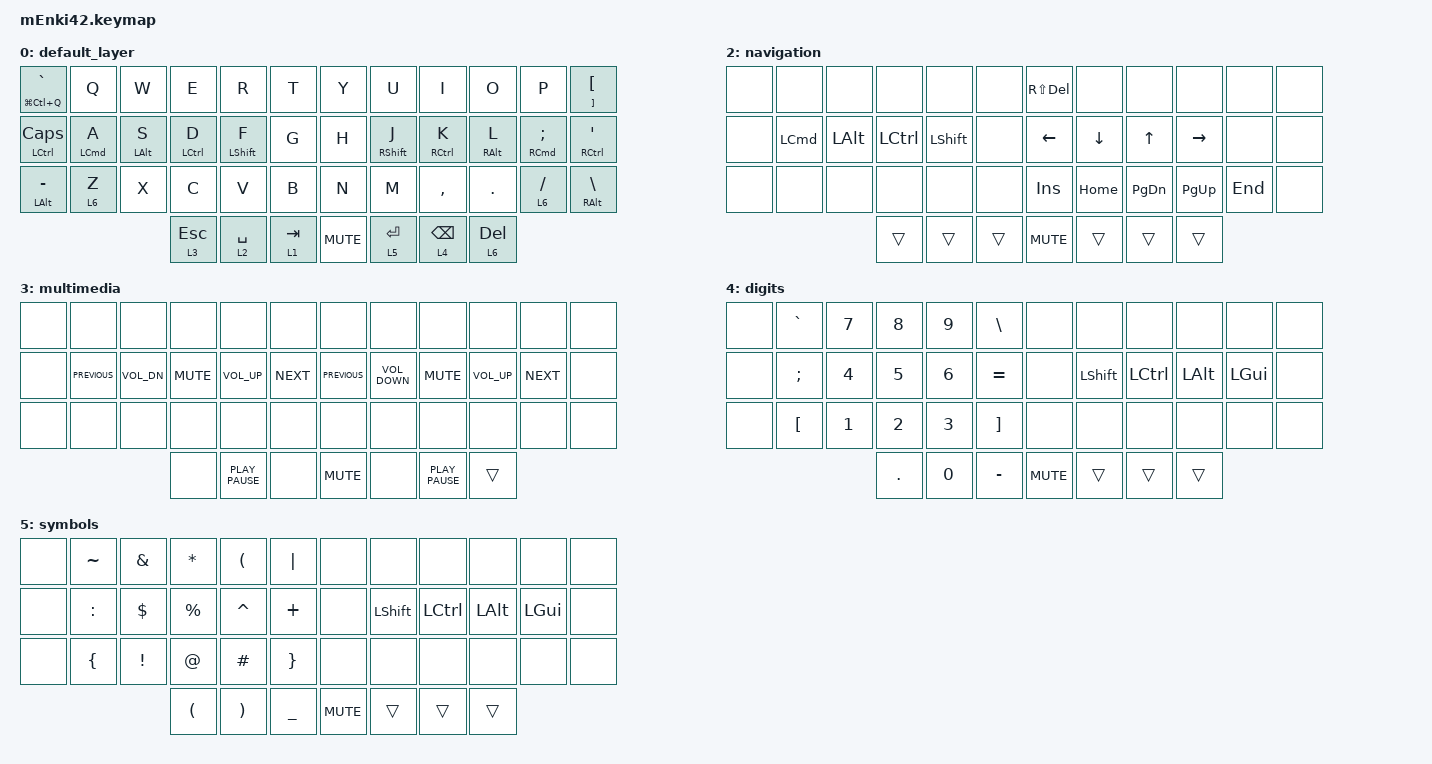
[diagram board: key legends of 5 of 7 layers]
/*
 * Copyright (c) 2020 The ZMK Contributors
 *
 * SPDX-License-Identifier: MIT
 */

#include <dt-bindings/zmk/mouse.h>
#include <behaviors.dtsi>
#include <dt-bindings/zmk/bt.h>
#include <dt-bindings/zmk/ext_power.h>
#include <dt-bindings/zmk/keys.h>

#define DEF 0
#define LWR 1
#define RSE 2
#define ADJ 3

&lt { quick_tap_ms = <220>; };

&mt {
    quick_tap_ms = <200>;
    tapping-term-ms = <250>;
    flavor = "tap-preferred";
};

/ {
    macros {
        numdot: numdot {
            label = "ZM_numdot";
            compatible = "zmk,behavior-macro";
            #binding-cells = <0>;
            wait-ms = <40>;
            tap-ms = <40>;
            bindings =
                <&macro_press>,
                <&kp LALT>,
                <&macro_tap>,
                <&kp KP_N4 &kp KP_N6>,
                <&macro_release>,
                <&kp LALT>;
        };

        grtsgn: grtsgn {
            label = "ZM_grtsgn";
            compatible = "zmk,behavior-macro";
            #binding-cells = <0>;
            wait-ms = <40>;
            tap-ms = <40>;
            bindings =
                <&macro_press>,
                <&kp LALT>,
                <&macro_tap>,
                <&kp KP_N6 &kp KP_N2>,
                <&macro_release>,
                <&kp LALT>;
        };
    };
};

/ {
    keymap {
        compatible = "zmk,keymap";

        default_layer {
            // ------------------------------------------------------------------------------------------------
            //| LGUI/] |  Q  |  W  |  E  |  R  |  T  |   |  Y  |  U   |  I  |  O  |  P  | RGUI/[ | 
            //| CTRL/` |  A  |  S  |  D  |  F  |  G  |   |  H  |  J   |  K  |  L  |  ;  | CTRL/' |
            //| LALT/\ |  Z  |  X  |  C  |  V  |  B  |   |  N  |  M   |  ,  |  .  |  /  | RALT/- |
            //                             | RSE | SPC | LWR |   | LWR | BKSP | RSE |

            bindings = <
&mt LG(LC(Q)) GRAVE  &kp Q       &kp W           &kp E        &kp R             &kp T                  &kp Y        &kp U              &kp I                &kp O            &kp P               &mt RIGHT_BRACKET LBKT
&mt LCTRL CAPSLOCK   &mt LCMD A  &mt LEFT_ALT S  &mt LCTRL D  &mt LEFT_SHIFT F  &kp G                  &kp H        &mt RIGHT_SHIFT J  &mt RIGHT_CONTROL K  &mt RIGHT_ALT L  &mt RCMD SEMICOLON  &mt RCTRL SQT
&mt LALT MINUS       &lt 6 Z     &kp X           &kp C        &kp V             &kp B                  &kp N        &kp M              &kp COMMA            &kp DOT          &lt 6 SLASH         &mt RALT BACKSLASH
                                                 &lt 3 ESC    &lt 2 SPACE       &lt 1 TAB  &kp C_MUTE  &lt 5 ENTER  &lt 4 BACKSPACE    &lt 6 DELETE
            >;

            sensor-bindings = <&inc_dec_kp C_VOL_UP C_VOL_DN>;
        };

        f {
            // -----------------------------------------------------------------------------------------
            //|LGUI/CAPS |  *  |  7 |  8  |  9  |  +  |    |  !  |  @  |  #  |  $  |  %  | RGUI/F1 |
            //|CTRL/MENU |  /  |  4 |  5  |  6  |  -  |    |  ^  |  &  |  *  |  (  |  )  | CTRL/F2 |
            //|  LALT/=  |  0  |  1 |  4  |  3  |  .  |    |  ls |  F4 |  F5 |  F6 |  F7 | RALT/F3 |
            //                      | ADJ | ___ | ___ |    | ___ | ___ | ADJ |

            bindings = <
&none  &none     &none         &none      &none           &none               &kp PRINTSCREEN  &kp F7  &kp F8  &kp F9  &kp F12  &mt RWIN F1
&none  &kp LCMD  &kp LEFT_ALT  &kp LCTRL  &kp LEFT_SHIFT  &none               &kp SCROLLLOCK   &kp F4  &kp F5  &kp F6  &kp F11  &mt RALT F2
&none  &none     &none         &none      &none           &none               &kp PAUSE_BREAK  &kp F1  &kp F2  &kp F3  &kp F10  &mt RALT F3
                               &trans     &trans          &trans  &kp C_MUTE  &trans           &trans
            >;

            sensor-bindings = <&inc_dec_kp UP_ARROW DOWN_ARROW>;
        };

        navigation {
            bindings = <
&none  &none     &none         &none      &none           &none               &kp RS(DEL)  &none     &none          &none        &none    &none
&none  &kp LCMD  &kp LEFT_ALT  &kp LCTRL  &kp LEFT_SHIFT  &none               &kp LEFT     &kp DOWN  &kp UP_ARROW   &kp RIGHT    &none    &none
&none  &none     &none         &none      &none           &none               &kp INS      &kp HOME  &kp PAGE_DOWN  &kp PAGE_UP  &kp END  &none
                               &trans     &trans          &trans  &kp C_MUTE  &trans       &trans    &trans
            >;

            sensor-bindings = <&inc_dec_kp RIGHT LEFT>;
        };

        multimedia {
            bindings = <
&none  &none           &none         &none       &none             &none                   &none           &none              &none       &none            &none       &none
&none  &kp K_PREVIOUS  &kp K_VOL_DN  &kp K_MUTE  &kp K_VOLUME_UP   &kp K_NEXT              &kp K_PREVIOUS  &kp K_VOLUME_DOWN  &kp K_MUTE  &kp K_VOLUME_UP  &kp K_NEXT  &none
&none  &none           &none         &none       &none             &none                   &none           &none              &none       &none            &none       &none
                                     &none       &kp K_PLAY_PAUSE  &none       &kp C_MUTE  &none           &kp K_PLAY_PAUSE   &trans
            >;

            sensor-bindings = <&inc_dec_kp C_NEXT C_PREVIOUS>;
        };

        digits {
            bindings = <
&none  &kp GRAVE  &kp N7  &kp N8   &kp N9  &kp BSLH               &none   &none      &none      &none     &none     &none
&none  &kp SEMI   &kp N4  &kp N5   &kp N6  &kp EQUAL              &none   &kp LSHFT  &kp LCTRL  &kp LALT  &kp LGUI  &none
&none  &kp LBKT   &kp N1  &kp N2   &kp N3  &kp RBKT               &none   &none      &none      &none     &none     &none
                          &kp DOT  &kp N0  &kp MINUS  &kp C_MUTE  &trans  &trans     &trans
            >;

            sensor-bindings = <&inc_dec_kp K_SCROLL_UP K_SCROLL_DOWN>;
        };

        symbols {
            bindings = <
&none  &kp TILDE       &kp AMPERSAND    &kp ASTERISK          &kp LEFT_PARENTHESIS   &kp PIPE                     &none   &none      &none      &none     &none     &none
&none  &kp COLON       &kp DOLLAR       &kp PERCENT           &kp CARET              &kp PLUS                     &none   &kp LSHFT  &kp LCTRL  &kp LALT  &kp LGUI  &none
&none  &kp LEFT_BRACE  &kp EXCLAMATION  &kp AT_SIGN           &kp HASH               &kp RIGHT_BRACE              &none   &none      &none      &none     &none     &none
                                        &kp LEFT_PARENTHESIS  &kp RIGHT_PARENTHESIS  &kp UNDERSCORE   &kp C_MUTE  &trans  &trans     &trans
            >;

            sensor-bindings = <&inc_dec_kp K_VOLUME_UP K_VOLUME_DOWN>;
        };

        adjust_layer {
            // -----------------------------------------------------------------------------------------
            //| BLDR |     |     |     |     |     |   |     |     |     |     |     | BLDR |
            //| BTCLR| BT0 | BT1 | BT2 | BT3 | BT4 |   | BT4 | BT3 | BT2 | BT1 | BT0 | BTCLR|
            //|pwrOFF|NUMLK|     |     |     |     |   |     |     |     |     |     |      |
            //                   |     |     |     |   |     |     |     |

            bindings = <
&bootloader        &none             &none         &none         &none         &none                     &none         &none         &none         &none         &none             &bootloader
&bt BT_CLR         &bt BT_SEL 0      &bt BT_SEL 1  &bt BT_SEL 2  &bt BT_SEL 3  &bt BT_SEL 4              &bt BT_SEL 4  &bt BT_SEL 3  &bt BT_SEL 2  &bt BT_SEL 1  &bt BT_SEL 0      &bt BT_CLR
&ext_power EP_OFF  &ext_power EP_ON  &none         &none         &none         &none                     &none         &none         &none         &none         &ext_power EP_ON  &ext_power EP_OFF
                                                   &trans        &none         &trans        &kp C_MUTE  &trans        &trans
            >;

            sensor-bindings = <&inc_dec_kp &numdot &grtsgn>;
        };
    };
};
